# CH32V00xxx register map
Vendor: WCH; File version: 2024.09.30
CH32V00xxx View File
Registers are 32-bit, read-write, reset 0x0 unless marked. A register's access mark holds for its fields unless they carry their own. Offsets are from the block's base; lines under a group give offsets from that group; [hi:lo] are bit positions; {n}, {i} and the like mark numbered series; 'fields as' and 'values as' point back to an identical list; <NAME> marks a mode.

## Memory map
0x1FFFF7E0 ESIG size 0x14 — Device electronic signature
0x40000000 TIM2 size 0x400 — General purpose timer
0x40002C00 WWDG size 0x400 — Window watchdog
0x40003000 IWDG size 0x400 — Independent watchdog
0x40005400 I2C1 size 0x400 — Inter integrated circuit
0x40007000 PWR size 0x400 — Power control
0x40010000 AFIO size 0x400 — Alternate function I/O
0x40010400 EXTI size 0x400
0x40010800 GPIOA size 0x400 — General purpose I/O
0x40011000 GPIOC size 0x400 — General purpose I/O
0x40011400 GPIOD size 0x400 — General purpose I/O
0x40012400 ADC1 size 0x400 — Analog to digital converter
0x40012C00 TIM1 size 0x400 — Advanced timer
0x40013000 SPI1 size 0x400 — Serial peripheral interface
0x40013800 USART1 size 0x400 — Universal synchronous asynchronous receiver transmitter
0x40020000 DMA1 size 0x400 — DMA1 controller
0x40021000 RCC size 0x400 — Reset and clock control
0x40022000 FLASH size 0x400
0x40023800 EXTEN size 0x400 — Extend configuration
0xE000D000 DBG size 0x400 — Debug support
0xE000E000 PFIC size 0x1100 — Programmable Fast Interrupt Controller

## Interrupts
16 WWDG — Window Watchdog interrupt
17 PVD (PWR) — PVD through EXTI line detection interrupt
18 FLASH — Flash global interrupt
19 RCC — Reset and clock control interrupt
20 EXTI7_0 (EXTI) — EXTI Line[7:0] interrupt
21 AWU (PWR) — AWU global interrupt
22 DMA1_Channel1 (DMA1) — DMA1 Channel 1 global interrupt
23 DMA1_Channel2 (DMA1) — DMA1 Channel 2 global interrupt
24 DMA1_Channel3 (DMA1) — DMA1 Channel 3 global interrupt
25 DMA1_Channel4 (DMA1) — DMA1 Channel 4 global interrupt
26 DMA1_Channel5 (DMA1) — DMA1 Channel 5 global interrupt
27 DMA1_Channel6 (DMA1) — DMA1 Channel 6 global interrupt
28 DMA1_Channel7 (DMA1) — DMA1 Channel 7 global interrupt
29 ADC (ADC1) — ADC global interrupt
30 I2C1_EV (I2C1) — I2C1 event interrupt
31 I2C1_ER (I2C1) — I2C1 error interrupt
32 USART1 — USART1 global interrupt
33 SPI1 — SPI1 global interrupt
34 TIM1BRK (TIM1) — TIM1 Break interrupt
35 TIM1UP (TIM1) — TIM1 Update interrupt
36 TIM1RG (TIM1) — TIM1 Trigger and Commutation interrupts
37 TIM1CC (TIM1) — TIM1 Capture Compare interrupt
38 TIM2 — TIM2 global interrupt

## AFIO — Alternate function I/O
Base 0x40010000
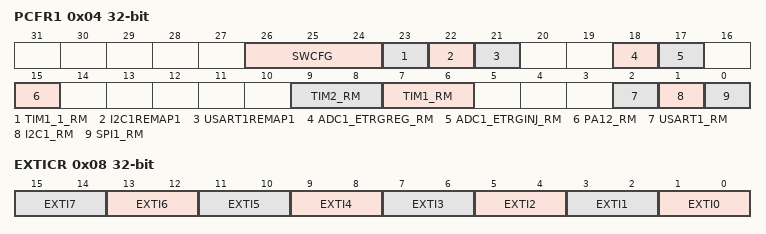
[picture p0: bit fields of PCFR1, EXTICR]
0x04 PCFR1 access per field — AF remap and debug I/O configuration register (AFIO_PCFR1)
  [26:24] SWCFG wo — Serial wire JTAG configuration
  [23] TIM1_1_RM rw — TIM1_CH1 channel selection
  [22] I2C1REMAP1 rw — I2C1 remapping
  [21] USART1REMAP1 rw — USART1 remapping
  [18] ADC1_ETRGREG_RM rw — ADC 1 external trigger regular conversion remapping
  [17] ADC1_ETRGINJ_RM rw — ADC 1 External trigger injected conversion remapping
  [15] PA12_RM rw — Port A1/Port A2 mapping on OSCIN/OSCOUT
  [9:8] TIM2_RM rw — TIM2 remapping
  [7:6] TIM1_RM rw — TIM1 remapping
  [2] USART1_RM rw — USART1 remapping
  [1] I2C1_RM rw — I2C1 remapping
  [0] SPI1_RM rw — SPI1 remapping
0x08 EXTICR — External interrupt configuration register (AFIO_EXTICR)
  [2n+1:2n] EXTI{n} (n=0..7) — EXTI{n} configuration

## DBG — Debug support
Base 0xE000D000
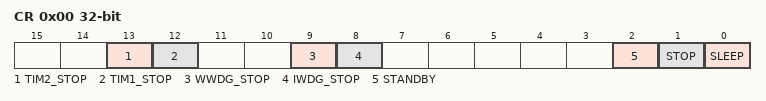
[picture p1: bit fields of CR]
0x00 CR — DBGMCU_CFGR1
  [13] TIM2_STOP
  [12] TIM1_STOP
  [9] WWDG_STOP
  [8] IWDG_STOP
  [2] STANDBY — Debug standby mode
  [1] STOP — Debug stop mode
  [0] SLEEP — Debug Sleep mode

## DMA1 — DMA1 controller
Base 0x40020000
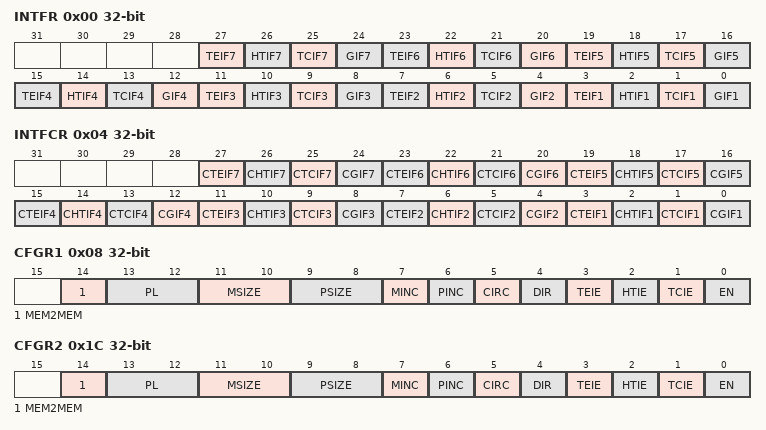
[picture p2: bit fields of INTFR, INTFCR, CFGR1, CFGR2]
0x00 INTFR ro — DMA interrupt status register (DMA_INTFR)
  [4n-1] TEIF{n} (n=1..7) — Channel {n} Transfer Error flag
  [4n-2] HTIF{n} (n=1..7) — Channel {n} Half Transfer Complete flag
  [4n-3] TCIF{n} (n=1..7) — Channel {n} Transfer Complete flag
  [4n-4] GIF{n} (n=1..7) — Channel {n} Global interrupt flag
0x04 INTFCR wo — DMA interrupt flag clear register (DMA_INTFCR)
  [4n-1] CTEIF{n} (n=1..7) — Channel {n} Transfer Error clear
  [4n-2] CHTIF{n} (n=1..7) — Channel {n} Half Transfer clear
  [4n-3] CTCIF{n} (n=1..7) — Channel {n} Transfer Complete clear
  [4n-4] CGIF{n} (n=1..7) — Channel {n} Global interrupt clear
0x08 CFGR1 — DMA channel configuration register (DMA_CFGR)
  [14] MEM2MEM — Memory to memory mode
  [13:12] PL — Channel Priority level
  [11:10] MSIZE — Memory size
  [9:8] PSIZE — Peripheral size
  [7] MINC — Memory increment mode
  [6] PINC — Peripheral increment mode
  [5] CIRC — Circular mode
  [4] DIR — Data transfer direction
  [3] TEIE — Transfer error interrupt enable
  [2] HTIE — Half Transfer interrupt enable
  [1] TCIE — Transfer complete interrupt enable
  [0] EN — Channel enable
0x0C CNTR1 — DMA channel 1 number of data register
  [15:0] NDT — Number of data to transfer
0x10 PADDR1 — DMA channel 1 peripheral address register
  [31:0] PA — Peripheral address
{0x0+0x14*i} MADDR{i} (i=1..7) — DMA channel {i} memory address register
  [31:0] MA — Memory address
0x1C CFGR2 — DMA channel configuration register (DMA_CFGR)
  fields as CFGR1
0x20 CNTR2 — DMA channel 2 number of data register
  [15:0] NDT — Number of data to transfer
0x24 PADDR2 — DMA channel 2 peripheral address register
  [31:0] PA — Peripheral address
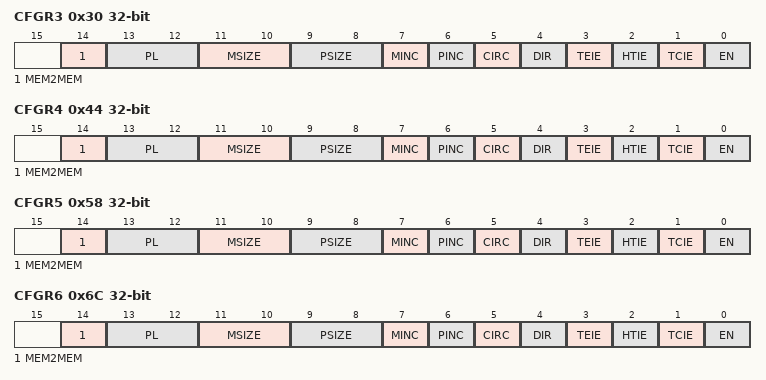
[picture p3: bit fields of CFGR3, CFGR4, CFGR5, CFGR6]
0x30 CFGR3 — DMA channel configuration register (DMA_CFGR)
  fields as CFGR1
0x34 CNTR3 — DMA channel 3 number of data register
  [15:0] NDT — Number of data to transfer
0x38 PADDR3 — DMA channel 3 peripheral address register
  [31:0] PA — Peripheral address
0x44 CFGR4 — DMA channel configuration register (DMA_CFGR)
  fields as CFGR1
0x48 CNTR4 — DMA channel 4 number of data register
  [15:0] NDT — Number of data to transfer
0x4C PADDR4 — DMA channel 4 peripheral address register
  [31:0] PA — Peripheral address
0x58 CFGR5 — DMA channel configuration register (DMA_CFGR)
  fields as CFGR1
0x5C CNTR5 — DMA channel 5 number of data register
  [15:0] NDT — Number of data to transfer
0x60 PADDR5 — DMA channel 5 peripheral address register
  [31:0] PA — Peripheral address
0x6C CFGR6 — DMA channel configuration register (DMA_CFGR)
  fields as CFGR1
0x70 CNTR6 — DMA channel 6 number of data register
  [15:0] NDT — Number of data to transfer
0x74 PADDR6 — DMA channel 6 peripheral address register
  [31:0] PA — Peripheral address
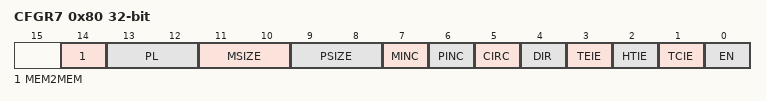
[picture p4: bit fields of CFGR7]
0x80 CFGR7 — DMA channel configuration register (DMA_CFGR)
  fields as CFGR1
0x84 CNTR7 — DMA channel 7 number of data register
  [15:0] NDT — Number of data to transfer
0x88 PADDR7 — DMA channel 7 peripheral address register
  [31:0] PA — Peripheral address
